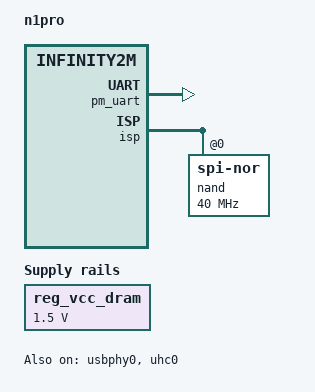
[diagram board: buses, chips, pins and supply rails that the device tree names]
// SPDX-License-Identifier: GPL-2.0-or-later
/*
 * Copyright (c) 2021 thingy.jp.
 * Author: Daniel Palmer <daniel@thingy.jp>
 */

/dts-v1/;
#include "mstar-infinity2m-ssd202d.dtsi"

#include <dt-bindings/gpio/gpio.h>
#include <dt-bindings/leds/common.h>

/ {
	model = "n1pro";
	compatible = "n1pro", "mstar,infinity2m";

	aliases {
		serial0 = &pm_uart;
	};

	chosen {
		stdout-path = "serial0:115200n8";
		bootargs = "console=ttyS0,115200 clk_ignore_unused earlyprintk";
	};

	reg_vcc_dram: regulator-vcc-dram {
		compatible = "regulator-fixed";
		regulator-name = "vcc_dram";
		regulator-min-microvolt = <1500000>;
		regulator-max-microvolt = <1500000>;
		regulator-boot-on;
	};
};

&pm_uart {
	status = "okay";
};

&isp {
	status = "okay";
	nand: nand@0 {
		#address-cells = <1>;
		#size-cells = <1>;
		compatible = "jedec,spi-nor";
		reg = <0>;
		spi-max-frequency = <40000000>;
		spi-rx-bus-width = <4>;
	};
};

&usbphy0 {
	status = "okay";
};

&uhc0 {
	status = "okay";
};

&miu {
	ddr-supply = <&reg_vcc_dram>;
};
